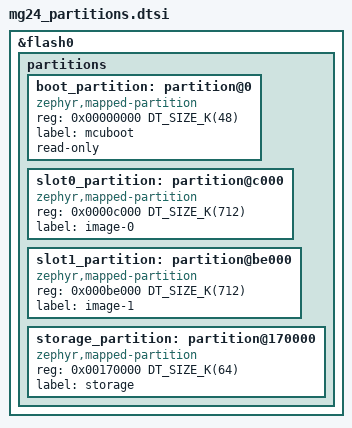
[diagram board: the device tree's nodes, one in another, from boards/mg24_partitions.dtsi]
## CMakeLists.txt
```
# MagNET Hanasu — Zephyr build (XIAO MG24).
#
# The MagNET core and the Forth engine are compiled straight from
# firmware-idf/ — NOT copied — so the two targets cannot drift. What differs
# lives here: compat/ (the FreeRTOS/esp_* subset those sources call, on Zephyr
# primitives), the PSA port of magnet_crypto.c, main.c, and the Z-B bundle stub.
#
#   cd ~/zephyrproject && west build -b xiao_mg24 <this dir> -d build/mn
cmake_minimum_required(VERSION 3.20.0)
find_package(Zephyr REQUIRED HINTS $ENV{ZEPHYR_BASE})
project(magnet_hanasu_zephyr)

set(IDF   ${CMAKE_CURRENT_LIST_DIR}/../firmware-idf)
set(MN    ${IDF}/components/magnet)
set(FORTH ${IDF}/components/forth)
set(CRAW  ${IDF}/components/craw_role_bundle)
set(NACL  ${IDF}/components/magnet_crypto)     # TweetNaCl Ed25519 (bundle signatures)

target_sources(app PRIVATE
    src/main.c
    src/magnet_crypto_psa.c
    src/ota.c
    compat/src/freertos_zephyr.c
    compat/src/nvs_zephyr.c
    compat/src/esp_misc_zephyr.c
    ${MN}/magnet_core.c
    ${MN}/magnet_envelope.c
    ${MN}/magnet_pkg.c
    ${MN}/magnet_link.c
    ${MN}/magnet_forth.c
    ${MN}/magnet_xfer.c
    ${MN}/magnet_bot.c
    ${MN}/magnet_ot.c
    ${FORTH}/forth_core.cpp
)

# compat/include first: it must win over nothing, but it is the ONLY source
# of the esp_* / freertos/* headers on this target.
target_include_directories(app PRIVATE
    compat/include
    ${MN}/include
    ${FORTH}
    ${CRAW}
)

if(CONFIG_MN_OTA_FORCE_UNHEALTHY)   # test builds only; see src/ota.c
  target_compile_definitions(app PRIVATE MN_OTA_FORCE_UNHEALTHY=1)
endif()
if(CONFIG_MN_PKG_RELEASE_KEYS)      # release.conf; see tools/keys/README.md
  target_compile_definitions(app PRIVATE MN_PKG_RELEASE_KEYS=1)
endif()

# BLE-GATT HCP binding: the Zephyr BT-host port when built with ble.conf,
# otherwise the IDF file's own MN_ENABLE_BLE=0 no-op stubs.
if(CONFIG_BT)
  target_sources(app PRIVATE src/magnet_ble_zephyr.c)
  # The BT stack is paid for from the malloc arena (ble.conf: 52 KB), which
  # left a BLE-fed BUNDLE COMMIT 2.5 KB from OOM with a 32 KB Forth heap.
  # Forth heap is allot/create space only (used=0 on the bench) -> 16 KB.
  target_compile_definitions(app PRIVATE MN_ENABLE_BLE=1 MN_FORTH_HEAP_KB=16)
  if(CONFIG_MN_BLE_RESIDENT)       # ble-resident.conf
    target_compile_definitions(app PRIVATE MN_BLE_RESIDENT=1)
  endif()
else()
  target_sources(app PRIVATE ${MN}/magnet_ble.c)
  target_compile_definitions(app PRIVATE MN_ENABLE_BLE=0)
endif()

target_compile_definitions(app PRIVATE
    _DEFAULT_SOURCE          # strlcpy/strcasecmp: newlib shows them by default, picolibc does not
    MN_ENABLE_OPENTHREAD=1
    MN_ENABLE_LED=0          # single PA7 LED; LED verb reports E_UNSUPPORTED
    MN_ENABLE_BOTS=0
)

# The engine takes its re-entrancy lock only under ESP_PLATFORM; this target
# is multi-threaded (link, pump, hooks), so it needs that lock too.
# MAX_WORD_LEN 64→32 saves 16 KB of dictionary BSS (512 entries); the
# longest word any MagNET/bundle code registers is 14 chars.
set_source_files_properties(${FORTH}/forth_core.cpp PROPERTIES
    COMPILE_DEFINITIONS "ESP_PLATFORM=1;MAX_WORD_LEN=32"
    COMPILE_OPTIONS "-Wno-unused-function;-Wno-unused-variable;-Wno-sign-compare;-Wno-write-strings;-Wno-missing-field-initializers")

# PBKDF2 inner loop (software SHA-256): -O3 over the project's -Os. Measured
# with the MN_KAT_TIME_PBKDF2 power-on KAT on the XIAO MG24 @ 78 MHz.
set_source_files_properties(src/magnet_crypto_psa.c PROPERTIES COMPILE_OPTIONS "-O3"
    COMPILE_DEFINITIONS MBEDTLS_DECLARE_PRIVATE_IDENTIFIERS)   # mbedtls_md_hmac KAT

# ---- signed role bundles (H6): craw_role_bundle + TweetNaCl + cJSON ----
# Its own library because the Ed25519 component ships a header ALSO named
# magnet_crypto.h (the core's is the channel/AEAD one). IDF keeps the two
# apart per component; here each target sees only its own.
zephyr_library_named(mn_bundle)
zephyr_library_sources(
    ${CRAW}/craw_role_bundle.c
    ${NACL}/magnet_crypto.c
    ${NACL}/tweetnacl.c
    ${NACL}/nacl_glue.c
    third_party/cJSON/cJSON.c         # MIT, v1.7.x from ESP-IDF 5.3.1 components/json
)
zephyr_library_include_directories(
    compat/include
    ${NACL}/include
    ${NACL}
    ${CRAW}
    ${FORTH}
    third_party/cJSON
)
zephyr_library_compile_definitions(_DEFAULT_SOURCE)
set_source_files_properties(${NACL}/tweetnacl.c PROPERTIES COMPILE_OPTIONS
    "-Wno-shadow;-Wno-sign-compare;-Wno-unused-parameter;-Wno-char-subscripts")
target_include_directories(app PRIVATE third_party/cJSON)
target_link_libraries(app PRIVATE mn_bundle)   # not auto-linked from an app-level zephyr_library
# TF-PSA-Crypto 1.0 moved mbedtls_md_hmac() behind MBEDTLS_DECLARE_PRIVATE_
# IDENTIFIERS; the bundle engine's legacy HMAC-SHA256 check still uses it.
set_source_files_properties(${CRAW}/craw_role_bundle.c PROPERTIES
    COMPILE_DEFINITIONS MBEDTLS_DECLARE_PRIVATE_IDENTIFIERS)
```

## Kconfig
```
# MagNET app options. Kconfig (not -D) because sysbuild forwards conf files to
# the app image but not arbitrary -D cache variables.
source "Kconfig.zephyr"

menu "MagNET Hanasu"

config MN_BLE_RESIDENT
	bool "BLE stays up after provisioning (companion node)"
	depends on BT
	help
	  Keep the BLE-GATT HCP binding up for the life of the node so a phone
	  can use it as its live window into the mesh (magnet_app Option A).
	  Default (n): advertise only while unprovisioned; CHANNEL SET tears
	  the stack down.

config MN_OTA_FORCE_UNHEALTHY
	bool "TEST ONLY: never confirm an OTA image (exercises rollback)"
	help
	  The running image never counts as healthy and the confirm deadline
	  drops to 20 s, so a swapped-in image reboots and MCUboot reverts.

config MN_PKG_RELEASE_KEYS
	bool "OTA key store: release keys (magnet_pkg_keys_release.h)"
	help
	  Trust the release OTA keys generated from PUBLIC halves (see
	  tools/keys/README.md) instead of the committed DEV keys. The build
	  fails if the release header is missing or holds DEV keys. Set by
	  release.conf.

endmenu
```

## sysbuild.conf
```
# Z-F: MCUboot + dual-slot images. Build with --sysbuild.
SB_CONFIG_BOOTLOADER_MCUBOOT=y
SB_CONFIG_BOOT_SIGNATURE_TYPE_ECDSA_P256=y
# SB_CONFIG_BOOT_SIGNATURE_KEY_FILE unset = MCUboot's DEV key. Replace before
# any node leaves the bench — anyone holding the dev key can sign firmware.
# swap-using-MOVE, not the default swap-using-offset: offset mode expects the
# upgrade image one sector INTO slot1, so an image written at the slot start
# is silently ignored (observed). Move mode = images at slot start; slot0
# keeps one spare sector for the shuffle, so max image = 712 KB - 8 KB - trailer.
SB_CONFIG_MCUBOOT_MODE_SWAP_USING_MOVE=y
```

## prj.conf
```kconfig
# MagNET Hanasu on Zephyr — XIAO MG24 (phase Z-B)

# ---- host link: USART0 is BOTH the HCP link and Zephyr's default console.
# Everything that could print to it is off, or it breaks §11.3 framing.
CONFIG_SERIAL=y
# RX by LDMA (async API) — see boards/xiao_mg24.overlay for why
CONFIG_UART_ASYNC_API=y
CONFIG_UART_INTERRUPT_DRIVEN=n
CONFIG_DMA=y
CONFIG_CONSOLE=n
CONFIG_UART_CONSOLE=n
CONFIG_LOG=n
CONFIG_SHELL=n
CONFIG_PRINTK=n
CONFIG_BOOT_BANNER=n

# ---- kernel
# = IDF CONFIG_ESP_MAIN_TASK_STACK_SIZE. Boot re-applies persisted role bundles
# on main (cJSON + TweetNaCl Ed25519 + Forth eval); 4 KB smashed the stack.
CONFIG_MAIN_STACK_SIZE=8192
# xTaskCreate → k_thread_stack_alloc
CONFIG_DYNAMIC_THREAD=y
CONFIG_DYNAMIC_THREAD_ALLOC=y
CONFIG_DYNAMIC_THREAD_PREFER_ALLOC=y
CONFIG_DYNAMIC_THREAD_POOL_SIZE=0
# k_malloc: task stacks (link 8K, pump 8K, stress 4K transient) + queues/timers
CONFIG_HEAP_MEM_POOL_SIZE=28672
# malloc: 32 KB Forth heap + core (low-water 34 KB free at 80 KB; 4 KB went to
# the pump stack / LDMA RX buffers)
CONFIG_COMMON_LIBC_MALLOC_ARENA_SIZE=77824
# SYSINFO / `mem` heap figures
CONFIG_SYS_HEAP_RUNTIME_STATS=y
CONFIG_REBOOT=y
# reset cause, EUI-64
CONFIG_HWINFO=y
CONFIG_GPIO=y

# ---- C++ for the Forth engine (forth_core.cpp uses <cstdio> etc.)
CONFIG_CPP=y
CONFIG_REQUIRES_FULL_LIBCPP=y

# ---- storage (NVS compat + OpenThread dataset share settings)
CONFIG_FLASH=y
CONFIG_FLASH_MAP=y
CONFIG_NVS=y
CONFIG_SETTINGS=y
CONFIG_SETTINGS_RUNTIME=n

# ---- networking / OpenThread (full router, CoAP, configured by magnet_ot.c)
CONFIG_NETWORKING=y
CONFIG_NET_L2_OPENTHREAD=y
CONFIG_OPENTHREAD_FTD=y
CONFIG_OPENTHREAD_COAP=y
CONFIG_OPENTHREAD_MANUAL_START=y
# OT allows ONE state-changed handler by default and Zephyr's L2 takes it;
# without room for magnet_ot.c's, every !ROLE event silently disappears.
CONFIG_OPENTHREAD_MAX_STATECHANGE_HANDLERS=3
# Zephyr's IP stack only ferries single 802.15.4 frames (≤127 B) between the
# radio driver and OpenThread — MagNET's CoAP lives in OT's own message pool.
# Defaults (16 KB of net_buf data) are sized for sockets we never open.
CONFIG_NET_PKT_RX_COUNT=6
CONFIG_NET_PKT_TX_COUNT=6
CONFIG_NET_BUF_RX_COUNT=12
CONFIG_NET_BUF_TX_COUNT=12
CONFIG_NET_MAX_CONTEXTS=2

# ---- crypto (§11.1 on PSA)
# OpenThread's DEFAULT security profile makes every PSA/mbedTLS symbol
# promptless (unsettable), and it has no HKDF. CUSTOM unlocks them — at the
# price of spelling out what the default profile selected. The list below is
# exactly the Z-A spike's resolved config (known good on this board) + HKDF.
CONFIG_OPENTHREAD_SECURITY_CUSTOM_CONFIG=y
CONFIG_SECURE_STORAGE=y
CONFIG_PSA_WANT_KEY_TYPE_AES=y
CONFIG_PSA_WANT_KEY_TYPE_HMAC=y
CONFIG_PSA_WANT_ALG_ECB_NO_PADDING=y
CONFIG_PSA_WANT_ALG_HMAC=y
CONFIG_PSA_WANT_ALG_CCM=y
CONFIG_PSA_WANT_ALG_CMAC=y
CONFIG_PSA_WANT_ALG_SHA_256=y
CONFIG_PSA_WANT_ECC_SECP_R1_256=y
CONFIG_PSA_WANT_KEY_TYPE_ECC_KEY_PAIR_IMPORT=y
CONFIG_PSA_WANT_KEY_TYPE_ECC_KEY_PAIR_EXPORT=y
CONFIG_PSA_WANT_KEY_TYPE_ECC_KEY_PAIR_GENERATE=y
CONFIG_PSA_WANT_KEY_TYPE_ECC_KEY_PAIR_DERIVE=y
CONFIG_PSA_WANT_KEY_TYPE_ECC_PUBLIC_KEY=y
CONFIG_PSA_WANT_ALG_ECDSA=y
CONFIG_PSA_WANT_ALG_DETERMINISTIC_ECDSA=y
CONFIG_PSA_WANT_ALG_ECDH=y
CONFIG_MBEDTLS=y
CONFIG_MBEDTLS_ENABLE_HEAP=y
# The SE has no DETERMINISTIC ECDSA, so mn_sign falls back to software bignum
# math on this heap. The 1 KB default fails with PSA_ERROR_INSUFFICIENT_MEMORY
# (caught by the RFC 6979 power-on KAT).
CONFIG_MBEDTLS_HEAP_SIZE=6144
CONFIG_MBEDTLS_MD_C=y
CONFIG_MBEDTLS_ASN1_PARSE_C=y
CONFIG_MBEDTLS_X509_CRT_PARSE_C=y
CONFIG_MBEDTLS_KEY_EXCHANGE_ECDHE_ECDSA_ENABLED=y
CONFIG_MBEDTLS_PK_WRITE_C=y
CONFIG_MBEDTLS_ECP_NIST_OPTIM=y
# MagNET additions
CONFIG_PSA_WANT_ALG_HKDF=y
# one-shot PBKDF2: native on the Secure Engine for Secure Vault High parts
CONFIG_PSA_WANT_ALG_PBKDF2_HMAC=y
CONFIG_MBEDTLS_BASE64_C=y

# ---- OTA (Z-F): mark a freshly swapped image good once the node is healthy
CONFIG_FLASH_MAP=y
CONFIG_STREAM_FLASH=y
CONFIG_IMG_MANAGER=y
CONFIG_MCUBOOT_IMG_MANAGER=y
```

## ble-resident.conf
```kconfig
# Companion node: BLE resident (use with ble.conf)
CONFIG_MN_BLE_RESIDENT=y
```

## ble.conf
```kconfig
# Z-E: BLE-GATT HCP binding (§11.2.1) — Zephyr BT host + Silabs controller.
#   west build ... -- -DEXTRA_CONF_FILE=ble.conf
# Concurrent BLE + 802.15.4 needs RAIL's multiprotocol library (the driver's
# scheduler-priority Kconfigs only matter on multiprotocol builds).
CONFIG_BT=y
CONFIG_BT_PERIPHERAL=y
CONFIG_BT_DEVICE_NAME="MagNET"
CONFIG_BT_DEVICE_NAME_DYNAMIC=y
CONFIG_BT_MAX_CONN=1
CONFIG_BT_SMP=y
# NOT BT_SMP_SC_ONLY: SC-only mode demands authenticated (MITM) keys, which a
# screenless Just Works node can never produce. Legacy stays as fallback, as
# on the C6 (CONFIG_BT_NIMBLE_SM_LEGACY=y).
# A phone that lost its bond (app reinstall, FACTORY RESET) may pair again —
# NimBLE's REPEAT_PAIRING retry (BLE-PAIRING.md §3).
CONFIG_BT_SMP_ALLOW_UNAUTH_OVERWRITE=y
CONFIG_BT_BONDABLE=y
CONFIG_BT_MAX_PAIRED=4
CONFIG_BT_SETTINGS=y
CONFIG_BT_GATT_DYNAMIC_DB=n
# ATT MTU 247 (client SHOULD request it — §11.2.1)
CONFIG_BT_L2CAP_TX_MTU=247
CONFIG_BT_BUF_ACL_RX_SIZE=251
CONFIG_BT_BUF_ACL_TX_SIZE=251
# Long (prepared) writes: ADMIN ADD <130-hex pubkey> exceeds one ATT payload
CONFIG_BT_ATT_PREPARE_COUNT=4
CONFIG_SILABS_SISDK_RAIL_MULTIPROTOCOL=y
# RAM: the BT host + controller glue costs ~19 KB. Pay for it from the malloc
# arena, whose measured low-water mark (boot bundle re-apply + BUNDLE COMMIT)
# was 34 KB free of 80 KB (46 KB peak use) — 56 KB leaves ~10 KB at that peak.
CONFIG_COMMON_LIBC_MALLOC_ARENA_SIZE=57344
# +4 KB kernel heap for the mn_ble_rx worker's 6 KB stack
CONFIG_HEAP_MEM_POOL_SIZE=28672
```

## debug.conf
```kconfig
# Debug overlay: crash reports on the console. Breaks HCP framing — bring-up
# only. Build with  -- -DEXTRA_CONF_FILE=debug.conf
CONFIG_CONSOLE=y
CONFIG_UART_CONSOLE=y
CONFIG_PRINTK=y
CONFIG_LOG=y
CONFIG_LOG_MODE_MINIMAL=y
CONFIG_ASSERT=y
CONFIG_THREAD_NAME=y
CONFIG_EXTRA_EXCEPTION_INFO=y
CONFIG_INIT_STACKS=y
CONFIG_THREAD_STACK_INFO=y
# stack overflows report as such instead of a garbage EXC_RETURN
CONFIG_MPU_STACK_GUARD=y
# console/log RAM has to come from somewhere: 4 KB off the malloc arena
CONFIG_COMMON_LIBC_MALLOC_ARENA_SIZE=73728
```

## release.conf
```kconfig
# Release build: trust the release OTA keys, not the committed DEV keys.
# Use with -DMN_SIGN_OFFLINE=1 and the PUBLIC MCUboot key — tools/keys/README.md.
CONFIG_MN_PKG_RELEASE_KEYS=y
```

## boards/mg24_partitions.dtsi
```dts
/*
 * XIAO MG24 flash map for MCUboot + dual-slot OTA (Z-F). Shared by the app
 * (boards/xiao_mg24.overlay) and MCUboot (sysbuild/mcuboot.overlay) so the two
 * can never disagree. 1536 KB, 8 KB pages:
 *
 *   0x000000  mcuboot   48 KB
 *   0x00C000  slot0    712 KB   running image
 *   0x0BE000  slot1    712 KB   OTA download / swap partner
 *   0x170000  storage   64 KB   settings: identity key, bonds, channel, OT
 *
 * storage stays at 0x170000 (where the pre-MCUboot build put it) so an
 * upgrade keeps the node's identity and bonds.
 */
&flash0 {
	/delete-node/ partitions;

	partitions {
		ranges;
		#address-cells = <1>;
		#size-cells = <1>;

		boot_partition: partition@0 {
			compatible = "zephyr,mapped-partition";
			reg = <0x00000000 DT_SIZE_K(48)>;
			label = "mcuboot";
			read-only;
		};
		slot0_partition: partition@c000 {
			compatible = "zephyr,mapped-partition";
			reg = <0x0000c000 DT_SIZE_K(712)>;
			label = "image-0";
		};
		slot1_partition: partition@be000 {
			compatible = "zephyr,mapped-partition";
			reg = <0x000be000 DT_SIZE_K(712)>;
			label = "image-1";
		};
		storage_partition: partition@170000 {
			compatible = "zephyr,mapped-partition";
			reg = <0x00170000 DT_SIZE_K(64)>;
			label = "storage";
		};
	};
};
```

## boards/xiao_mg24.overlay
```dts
/* App flash map — see mg24_partitions.dtsi (shared with MCUboot). */
#include "mg24_partitions.dtsi"


/* USART0 (the HCP host link) receives by LDMA, not by interrupt: its RX FIFO
 * is 2 bytes, and the CPU stalls for longer than 2 character times at
 * 115200 whenever flash is erased (an 8 KB page, ~15-20 ms: OTA staging,
 * settings) or the BLE controller's radio interrupts run — measured 0.9 % of
 * HCP lines corrupted with BLE up, and a lost XFER DATA line during OTA. */
&dma0 {
	status = "okay";
};

&usart0 {
	dmas = <&dma0 DMA_REQSEL_USART0RXDATAV>, <&dma0 DMA_REQSEL_USART0TXBL>;
	dma-names = "rx", "tx";
};
```

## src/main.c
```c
/*
 * main.c — MagNET Hanasu node on Zephyr (XIAO MG24), phase Z-B.
 *
 * Same bring-up order as firmware-idf/src/main.c (§12.5), which is
 * load-bearing: transport → forth_init (claim heap first) → storage → core +
 * vocab → link → RADIOS LAST.
 *
 * Host link: USART0 at 115200, which the XIAO's SAMD11 bridges to USB CDC.
 * This UART is ALSO Zephyr's default console, so prj.conf turns the console,
 * shell and logging off — any stray line here breaks HCP framing (§11.3).
 */
#include <zephyr/kernel.h>
#include <zephyr/device.h>
#include <zephyr/drivers/uart.h>
#include <zephyr/sys/ring_buffer.h>
#include <stdio.h>
#include <string.h>

#include "esp_heap_caps.h"
#include "nvs_flash.h"
#include "forth_core.h"
#include "craw_role_bundle.h"
#include "magnet_ota.h"
#include "magnet.h"

/* Half the C6's 64 KB. The Forth heap only backs allot/create data —
 * colon definitions (incl. installed role bundles) live in the engine's
 * static dictionary/code arrays — and SYSINFO showed forth-heap used=0 with
 * two bundles installed, while a BUNDLE COMMIT (6 KB accumulator + cJSON
 * tree + Ed25519) drove the shared malloc arena down to 1.4 KB free. */
#ifndef MN_FORTH_HEAP_KB
#define MN_FORTH_HEAP_KB 32        /* BLE build: 16 (CMakeLists.txt) */
#endif
#define FORTH_HEAP_SIZE (MN_FORTH_HEAP_KB * 1024)

static const struct device *const s_uart = DEVICE_DT_GET(DT_CHOSEN(zephyr_console));

/* ---- RX: LDMA → ring buffer → link_getc ----
 * Received by DMA, not per-byte interrupts: the USART FIFO is 2 bytes and the
 * CPU stalls longer than that at 115200 during flash erases and BLE radio
 * work (see boards/xiao_mg24.overlay). Two 384-byte buffers ping-pong — each
 * holds ~33 ms of line, so a stall up to ~66 ms loses nothing — and a 1 ms
 * idle timeout hands partial buffers over promptly. */
RING_BUF_DECLARE(s_rx_ring, 1024);
static K_SEM_DEFINE(s_rx_sem, 0, 1);
static uint8_t s_dma_buf[2][384];
static uint8_t s_dma_next;
/* The UART has no flow control: if the dispatcher falls > 1 KB behind the
 * wire, bytes are lost. Counted here, reported by link_getc as a !WARN so a
 * host knows its data was dropped (hosts should pace on replies; see
 * tools/ota_push.py). */
static atomic_t s_rx_dropped;

static void uart_cb(const struct device *dev, struct uart_event *evt, void *ud) {
    ARG_UNUSED(ud);
    switch (evt->type) {
    case UART_RX_RDY:
    {
        uint32_t put = ring_buf_put(&s_rx_ring, evt->data.rx.buf + evt->data.rx.offset,
                                    evt->data.rx.len);
        if (put < evt->data.rx.len) atomic_add(&s_rx_dropped, evt->data.rx.len - put);
        k_sem_give(&s_rx_sem);
    }
        break;
    case UART_RX_BUF_REQUEST:
        uart_rx_buf_rsp(dev, s_dma_buf[s_dma_next], sizeof(s_dma_buf[0]));
        s_dma_next ^= 1;
        break;
    case UART_RX_DISABLED:                  /* after an error/stop: start over */
        s_dma_next = 1;
        uart_rx_enable(dev, s_dma_buf[0], sizeof(s_dma_buf[0]), 1000);
        break;
    default:
        break;
    }
}

/* One char, or -1 after ~10 ms — the contract the IDF getc has.
 *
 * NUL bytes are dropped: the SAMD11 bridge injects a 0x00 into the UART when
 * the host opens the port, and a line that starts with NUL parses as empty
 * (the dispatcher answers "-ERR E_SYNTAX empty" and loses the whole command).
 * HCP is text, so a NUL is never meaningful. */
static int link_getc(void) {
    uint8_t c;
    static atomic_val_t reported;
    atomic_val_t dropped = atomic_get(&s_rx_dropped);
    if (dropped != reported) {                   /* dispatcher context: may emit */
        mn_emit_event("!WARN link-rx-overrun dropped=%ld (host: wait for each reply)",
                      (long)(dropped - reported));
        reported = dropped;
    }
    for (;;) {
        if (ring_buf_get(&s_rx_ring, &c, 1) != 1) {
            k_sem_take(&s_rx_sem, K_MSEC(10));
            if (ring_buf_get(&s_rx_ring, &c, 1) != 1) return -1;
        }
        if (c != 0) return c;
    }
}

/* Polled TX. Unlike the C6's on-die USB, the SAMD11 bridge always drains the
 * UART whether or not a host has the port open, so this cannot stall the way
 * link_putc on IDF could (which is why that one drops on a full buffer). */
static void link_putc(int c) { uart_poll_out(s_uart, (unsigned char)c); }

static void raw_print(const char *s) { while (*s) link_putc(*s++); }

static void report_heap(const char *label) {
    char buf[128];
    snprintf(buf, sizeof(buf), "# heap[%s] free=%u min=%u\r\n", label,
             (unsigned)heap_caps_get_free_size(MALLOC_CAP_INTERNAL),
             (unsigned)heap_caps_get_minimum_free_size(MALLOC_CAP_INTERNAL));
    raw_print(buf);
}

int main(void) {
    /* 1. transport up first so we can talk even if everything else stalls */
    if (!device_is_ready(s_uart)) return 0;
    uart_callback_set(s_uart, uart_cb, NULL);
    s_dma_next = 1;
    uart_rx_enable(s_uart, s_dma_buf[0], sizeof(s_dma_buf[0]), 1000);   /* 1 ms idle */

    raw_print("\r\n# MagNET Hanasu — Zephyr/MG24 (Z-B)\r\n");
    report_heap("boot");

    /* 2. claim the Forth dictionary heap while RAM is unfragmented */
    if (forth_init(FORTH_HEAP_SIZE) != 0) {
        raw_print("-ERR E_INTERNAL forth_init failed\r\n");
        return 0;
    }
    report_heap("after forth_init");

    /* 3. storage, then MagNET core + Forth vocab */
    if (nvs_flash_init() != ESP_OK) raw_print("# WARN settings init failed\r\n");
    {   /* power-on crypto KATs: PSA port == C6 mbedTLS */
        extern void mn_crypto_psa_kat(char *out, size_t cap);
        char kat[200];
        mn_crypto_psa_kat(kat, sizeof kat);
        raw_print(kat); raw_print("\r\n");
    }
    mn_core_init();
    mn_register_forth_vocab();
    craw_role_bundle_init();
    {
        int ncaps = 0;
        const char **caps = mn_bundle_caps(&ncaps);
        if (mn_ota_bundles_suspended()) {     /* CLEARS_BUNDLES image on trial (§7.4) */
            raw_print("# ota: CLEARS_BUNDLES image on trial — saved bundles held back\r\n");
        } else {
            if (craw_role_bundle_apply_saved(caps, ncaps) > 0)
                raw_print("# autorun: persisted role bundle(s) re-applied\r\n");
            int found, failed;               /* OTA health: a failed re-apply blocks confirm */
            craw_role_bundle_boot_stats(&found, &failed);
            mn_boot_bundles_set(found, failed);
        }
    }
    if (mn_script_run() == 0) raw_print("# autorun: boot script executed\r\n");

    /* 4. dual-mode host link (HCP default) + serialized TX writer */
    mn_link_start(link_getc, link_putc);
    mn_set_state(MN_BOOTING);
    mn_emit_event("!READY proto=2.1 fw=" MN_FW_VERSION " id=%02x%02x%02x%02x name=%s state=BOOTING",
                  mn_device_id()[0], mn_device_id()[1], mn_device_id()[2], mn_device_id()[3],
                  mn_name_get());
    mn_emit_event("# type CAPS, or HELP. FORTH drops to the engine.");
    {   /* Z-F: report the image and arm the confirm-when-healthy policy */
        extern void mn_ota_boot(void);
        extern void mn_ota_sink_init(void);
        mn_ota_boot();
        mn_ota_sink_init();          /* mesh OTA: "mnpkg:1" packages -> slot1 */
    }

#if MN_BLE_RESIDENT
    /* companion node: attachable for life (see firmware-idf/src/main.c) */
    if (mn_ble_start() == 0) raw_print("# ble: resident (companion node)\r\n");
#elif MN_ENABLE_BLE
    /* provisioning-only: advertise only while still on the default channel,
     * so a power cycle never re-opens a bonding window on a deployed node */
    if (mn_channel_is_default()) {
        if (mn_ble_start() == 0) raw_print("# ble: provisioning window open\r\n");
    } else {
        raw_print("# ble: skipped (already provisioned)\r\n");
    }
#endif

    /* 5. radios LAST. The XIAO MG24's RF switch (PB5 enable, PB4 antenna
     * select) is set by gpio-hogs in the board DTS — nothing to do here,
     * unlike the XIAO C6. */
    mn_set_state(MN_CONFIGURING);
    mn_openthread_start();

    report_heap("after openthread_start");
    return 0;                          /* link, pump and OT run in their own threads */
}
```

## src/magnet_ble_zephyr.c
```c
/*
 * magnet_ble_zephyr.c — BLE-GATT HCP binding (§11.2.1) on the Zephyr BT host.
 *
 * Same contract as firmware-idf/components/magnet/magnet_ble.c (NimBLE):
 * mn_ble_start/stop/running/link_secure/notify, the same GATT service and
 * UUIDs, and every rule docs/BLE-PAIRING.md paid for:
 *   - HCP-AUTH (…0003) is read-encrypted: reading it is what makes a central
 *     pair (centrals ignore a peripheral's Security Request).
 *   - bonding is enforced per verb (E_NOT_BONDED in magnet_link.c), never at
 *     the ATT layer — HCP-CMD is a plain write.
 *   - never dispatch in the ATT write callback: lines go to a worker.
 *   - notifications retry on buffer exhaustion; one lost chunk = no newline.
 *   - message boundary: a write shorter or longer than (MTU-3) completes a
 *     line; exactly (MTU-3) may continue. Long (prepared) writes are
 *     reassembled by offset and flushed once the execute sequence ends.
 *   - Just Works + numeric-comparison auto-accept (screenless node), and a
 *     peer that lost its bond may pair again (SMP_ALLOW_UNAUTH_OVERWRITE).
 *
 * Unlike the C6 build (provisioning-only by default), the MG24's radio is
 * built for concurrent BLE + 802.15.4 (RAIL multiprotocol), so the resident
 * companion mode is the natural one here; MN_BLE_RESIDENT still selects it.
 *
 * Context discipline: BT host callbacks run on the BT RX thread, which must
 * never block — they use mn_post_note() (pump-emitted), never mn_emit_event.
 */
#include <zephyr/kernel.h>
#include <zephyr/bluetooth/bluetooth.h>
#include <zephyr/bluetooth/conn.h>
#include <zephyr/bluetooth/gatt.h>
#include <zephyr/bluetooth/uuid.h>
#include <zephyr/settings/settings.h>
#include <stdio.h>
#include <string.h>

#include "magnet.h"
#include "freertos/FreeRTOS.h"

/* 6d61676e-2d68-6370-0001-0000000000NN — ASCII "magn" "-h" "cp" */
#define MN_UUID(nn) BT_UUID_128_ENCODE(0x6d61676e, 0x2d68, 0x6370, 0x0001, (nn##ULL))
static const struct bt_uuid_128 SVC_UUID  = BT_UUID_INIT_128(MN_UUID(0x000000000000));
static const struct bt_uuid_128 CMD_UUID  = BT_UUID_INIT_128(MN_UUID(0x000000000001));
static const struct bt_uuid_128 EVT_UUID  = BT_UUID_INIT_128(MN_UUID(0x000000000002));
static const struct bt_uuid_128 AUTH_UUID = BT_UUID_INIT_128(MN_UUID(0x000000000003));

static struct bt_conn *s_conn;
static bool s_running;
static bool s_encrypted;

/* ---- inbound: assemble lines, hand them to a worker ---- */
#define MN_BLE_LINE_MAX 256
static char   s_rx[512];
static size_t s_rx_len;
static QueueHandle_t s_rx_q;

static void post_line(void) {
    if (!s_rx_len) return;
    s_rx[s_rx_len] = '\0';
    if (s_rx_q) {
        char item[MN_BLE_LINE_MAX];
        strncpy(item, s_rx, sizeof(item) - 1);
        item[sizeof(item) - 1] = '\0';
        xQueueSend(s_rx_q, item, 0);          /* never block the BT RX thread */
    }
    s_rx_len = 0;
}

static void feed(const uint8_t *data, size_t len, bool write_complete) {
    for (size_t i = 0; i < len; i++) {
        char c = (char)data[i];
        if (c == '\n' || c == '\r') {
            post_line();
            write_complete = false;           /* newline already flushed it */
        } else if (s_rx_len < sizeof(s_rx) - 1) {
            s_rx[s_rx_len++] = c;
        }
    }
    if (write_complete) post_line();
}

static void ble_worker(void *arg) {
    ARG_UNUSED(arg);
    char item[MN_BLE_LINE_MAX];
    for (;;) {
        if (xQueueReceive(s_rx_q, item, portMAX_DELAY) == pdTRUE)
            mn_link_feed_line(item);          /* same dispatcher as the UART */
    }
}

/* A prepared (long) write arrives as a burst of EXECUTE callbacks with no
 * "last chunk" marker; flush the reassembled line shortly after the burst. */
static void long_write_flush(struct k_work *w) {
    ARG_UNUSED(w);
    post_line();
}
static K_WORK_DELAYABLE_DEFINE(s_long_flush, long_write_flush);

static ssize_t cmd_write(struct bt_conn *conn, const struct bt_gatt_attr *attr,
                         const void *buf, uint16_t len, uint16_t offset, uint8_t flags) {
    ARG_UNUSED(attr);
    if (flags & BT_GATT_WRITE_FLAG_PREPARE) return 0;      /* accept; data at execute */
    if (flags & BT_GATT_WRITE_FLAG_EXECUTE) {
        if (offset == 0) s_rx_len = 0;
        feed(buf, len, false);
        k_work_reschedule(&s_long_flush, K_MSEC(20));
        return len;
    }
    uint16_t payload = bt_gatt_get_mtu(conn) - 3;
    feed(buf, len, len != payload);
    return len;
}

static ssize_t auth_read(struct bt_conn *conn, const struct bt_gatt_attr *attr,
                         void *buf, uint16_t len, uint16_t offset) {
    static const char ok[] = "bonded";       /* reaching here = link encrypted */
    return bt_gatt_attr_read(conn, attr, buf, len, offset, ok, sizeof(ok) - 1);
}

static ssize_t evt_read(struct bt_conn *conn, const struct bt_gatt_attr *attr,
                        void *buf, uint16_t len, uint16_t offset) {
    return bt_gatt_attr_read(conn, attr, buf, len, offset, "", 0);
}

/* Subscription is NOT tracked here: for a bonded peer Zephyr restores the
 * stored CCC on reconnect and CoreBluetooth does not rewrite it, so a flag
 * cleared in connected() silently muted every reply after a reboot. The
 * stack is asked at send time instead (bt_gatt_is_subscribed). */
static void evt_ccc_changed(const struct bt_gatt_attr *attr, uint16_t value) {
    ARG_UNUSED(attr); ARG_UNUSED(value);
}

BT_GATT_SERVICE_DEFINE(mn_hcp_svc,
    BT_GATT_PRIMARY_SERVICE(&SVC_UUID),
    /* HCP-CMD: host → node. Plain write — bonding is per-verb (§11.3.4). */
    BT_GATT_CHARACTERISTIC(&CMD_UUID.uuid,
        BT_GATT_CHRC_WRITE | BT_GATT_CHRC_WRITE_WITHOUT_RESP,
        BT_GATT_PERM_WRITE | BT_GATT_PERM_PREPARE_WRITE, NULL, cmd_write, NULL),
    /* HCP-EVT: node → host (attrs[4] is its value, [5] its CCC) */
    BT_GATT_CHARACTERISTIC(&EVT_UUID.uuid, BT_GATT_CHRC_NOTIFY | BT_GATT_CHRC_READ,
        BT_GATT_PERM_READ, evt_read, NULL, NULL),
    BT_GATT_CCC(evt_ccc_changed, BT_GATT_PERM_READ | BT_GATT_PERM_WRITE),
    /* HCP-AUTH: read it to force pairing */
    BT_GATT_CHARACTERISTIC(&AUTH_UUID.uuid, BT_GATT_CHRC_READ,
        BT_GATT_PERM_READ_ENCRYPT, auth_read, NULL, NULL),
);
#define EVT_ATTR (&mn_hcp_svc.attrs[4])

/* ---- outbound: chunk to (MTU-3), client reassembles at '\n' ---- */
void mn_ble_notify(const char *line) {
    struct bt_conn *conn = s_conn;
    if (!s_running || !conn ||
        !bt_gatt_is_subscribed(conn, EVT_ATTR, BT_GATT_CCC_NOTIFY)) return;
    size_t chunk = bt_gatt_get_mtu(conn) - 3;
    size_t len = strlen(line);
    char buf[256];
    if (chunk > sizeof(buf) - 1) chunk = sizeof(buf) - 1;

    for (size_t off = 0; off <= len; off += chunk) {
        size_t n = len - off;
        bool last = n <= chunk;
        if (!last) n = chunk;
        memcpy(buf, line + off, n);
        if (last) buf[n++] = '\n';            /* frame terminator */
        int rc = -ENOMEM;
        for (int attempt = 0; attempt < 12 && rc != 0; attempt++) {
            rc = bt_gatt_notify(conn, EVT_ATTR, buf, n);
            if (rc == -ENOMEM || rc == -ENOBUFS) k_msleep(10);
            else if (rc != 0) return;         /* link gone / not subscribed */
        }
        if (rc != 0 || last) return;
    }
}

/* ---- connection + security callbacks (BT RX thread: post, don't emit) ---- */
static void connected(struct bt_conn *conn, uint8_t err) {
    if (err) return;
    s_conn = bt_conn_ref(conn);
    s_encrypted = false;
    mn_post_note("!STATE PROVISIONING ble-connected");
    /* Ask for security; per BLE-PAIRING.md centrals mostly ignore this and
     * pair on the HCP-AUTH read instead, but it costs nothing. */
    (void)bt_conn_set_security(conn, BT_SECURITY_L2);
}

static void disconnected(struct bt_conn *conn, uint8_t reason) {
    if (conn != s_conn) return;
    bt_conn_unref(s_conn);
    s_conn = NULL;
    s_encrypted = false;
    mn_post_note("# ble: disconnected (reason 0x%02x)", reason);
}

static void start_adv(void);

/* The connection object is free again: only now can connectable advertising
 * restart (doing it in disconnected() fails for lack of a conn slot). */
static void recycled(void) {
    if (s_running) start_adv();
}

static void security_changed(struct bt_conn *conn, bt_security_t level,
                             enum bt_security_err err) {
    ARG_UNUSED(conn);
    s_encrypted = (err == BT_SECURITY_ERR_SUCCESS) && level >= BT_SECURITY_L2;
    mn_post_note("# ble: link %s (level=%d err=%d)",
                 s_encrypted ? "encrypted" : "NOT encrypted", level, err);
}

BT_CONN_CB_DEFINE(mn_conn_cb) = {
    .connected = connected,
    .disconnected = disconnected,
    .recycled = recycled,
    .security_changed = security_changed,
};

/* Numeric comparison can still be requested under Secure Connections even
 * though we have no I/O; a screenless node accepts (BLE-PAIRING.md §2). */
static void passkey_confirm(struct bt_conn *conn, unsigned int passkey) {
    ARG_UNUSED(passkey);
    bt_conn_auth_passkey_confirm(conn);
}
static void pairing_cancel(struct bt_conn *conn) { ARG_UNUSED(conn); }
static struct bt_conn_auth_cb s_auth = {
    .passkey_confirm = passkey_confirm,
    .cancel = pairing_cancel,
};

static void mtu_updated(struct bt_conn *conn, uint16_t tx, uint16_t rx) {
    ARG_UNUSED(conn);
    mn_post_note("# ble: mtu negotiated tx=%u rx=%u", tx, rx);
}
static struct bt_gatt_cb s_gatt_cb = { .att_mtu_updated = mtu_updated };

/* ---- advertising: 128-bit service UUID in the advert, name in the scan
 * response (a host must be able to filter by service — BLE-PAIRING.md) ---- */
static const struct bt_data s_ad[] = {        /* file scope: BT_DATA_BYTES */
    BT_DATA_BYTES(BT_DATA_FLAGS, BT_LE_AD_GENERAL | BT_LE_AD_NO_BREDR),
    BT_DATA_BYTES(BT_DATA_UUID128_ALL, MN_UUID(0x000000000000)),
};

static void start_adv(void) {
    const char *name = bt_get_name();
    struct bt_data sd[] = { BT_DATA(BT_DATA_NAME_COMPLETE, name, strlen(name)) };
    int rc = bt_le_adv_start(BT_LE_ADV_CONN_FAST_1, s_ad, ARRAY_SIZE(s_ad), sd, ARRAY_SIZE(sd));
    if (rc && rc != -EALREADY) mn_post_note("!WARN ble-adv-start rc=%d", rc);
}

int mn_ble_start(void) {
    if (s_running) return 0;
    static bool once;
    if (!once) {
        bt_conn_auth_cb_register(&s_auth);
        bt_gatt_cb_register(&s_gatt_cb);
        s_rx_q = xQueueCreate(6, MN_BLE_LINE_MAX);
        /* 6 KB like IDF's mn_ble_rx: BLE-fed verbs run here (incl. BUNDLE) */
        xTaskCreate(ble_worker, "mn_ble_rx", 6144, NULL, 5, NULL);
        once = true;
    }
    int rc = bt_enable(NULL);
    if (rc && rc != -EALREADY) return -1;
    /* bonds + identity live in settings under "bt" */
    settings_load_subtree("bt");

    char name[24];
    const uint8_t *id = mn_device_id();
    snprintf(name, sizeof(name), "MagNET-%02x%02x", id[2], id[3]);
    bt_set_name(name);

    s_running = true;
    start_adv();
#if MN_BLE_RESIDENT
    mn_post_note("# ble: advertising (resident — survives provisioning)");
#else
    mn_post_note("# ble: advertising for provisioning (torn down once a channel is set)");
#endif
    return 0;
}

int mn_ble_stop(void) {
    if (!s_running) return 0;
    s_running = false;
    bt_le_adv_stop();
    if (s_conn) bt_conn_disconnect(s_conn, BT_HCI_ERR_REMOTE_USER_TERM_CONN);
    int rc = bt_disable();
    mn_post_note("# ble: torn down (channel provisioned); radio is Thread-only now");
    return rc;
}

bool mn_ble_running(void) { return s_running; }
bool mn_ble_link_secure(void) { return s_encrypted; }
```

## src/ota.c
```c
/*
 * ota.c — MCUboot image health policy (Z-F).
 *
 * After MCUboot swaps in a new image it runs in "test" state: unless the app
 * confirms it, the NEXT reset swaps the old image back. We confirm only once
 * the node is demonstrably healthy — Thread attached, state READY (a lone
 * node still gets there by becoming leader) — and if that has not happened
 * within MN_OTA_CONFIRM_DEADLINE, we reboot so MCUboot rolls back rather
 * than leave a broken image running on a node nobody can reach.
 */
#include <zephyr/kernel.h>
#include <zephyr/dfu/mcuboot.h>
#include <zephyr/storage/flash_map.h>
#include <zephyr/sys/reboot.h>

#include "magnet.h"
#include "magnet_ota.h"

/* MN_OTA_FORCE_UNHEALTHY (test builds only): never counts as healthy and
 * gives up after 20 s — exercises the automatic rollback path end to end. */
#if MN_OTA_FORCE_UNHEALTHY
#define MN_OTA_CONFIRM_DEADLINE_S 20
#define MN_NODE_HEALTHY() false
#else
#define MN_OTA_CONFIRM_DEADLINE_S (10 * 60)
#define MN_NODE_HEALTHY() mn_ota_node_healthy()   /* READY + bundles re-applied (§7.4) */
#endif
#define MN_OTA_POLL_MS            2000

static int64_t s_deadline_ms;

static void confirm_poll(struct k_work *w);
static K_WORK_DELAYABLE_DEFINE(s_confirm_work, confirm_poll);

static void confirm_poll(struct k_work *w) {
    ARG_UNUSED(w);
    if (MN_NODE_HEALTHY()) {
        int rc = boot_write_img_confirmed();
        mn_emit_event(rc == 0 ? "!OTA confirmed (node healthy)"
                              : "!WARN ota-confirm-failed rc=%d", rc);
        mn_ota_settled();                    /* §13.4 report, if an apply is on record */
        return;
    }
    if (k_uptime_get() >= s_deadline_ms) {
        mn_emit_event("!WARN ota-unhealthy: not READY in %ds, rebooting to roll back",
                      MN_OTA_CONFIRM_DEADLINE_S);
        k_msleep(200);                       /* let the line drain */
        sys_reboot(SYS_REBOOT_COLD);
    }
    k_work_reschedule(&s_confirm_work, K_MSEC(MN_OTA_POLL_MS));
}

/* "# ota: running ..." — at boot and from ota-status. True if confirmed. */
static bool report_running(void) {
    struct mcuboot_img_header hdr;
    int rc = boot_read_bank_header(PARTITION_ID(slot0_partition), &hdr, sizeof(hdr));
    bool confirmed = boot_is_img_confirmed();
    if (rc == 0) {
        mn_emit_event("# ota: running v%u.%u.%u+%u (slot0) %s",
                      hdr.h.v1.sem_ver.major, hdr.h.v1.sem_ver.minor,
                      hdr.h.v1.sem_ver.revision, hdr.h.v1.sem_ver.build_num,
                      confirmed ? "confirmed" : "TEST — confirms when READY");
    } else {
        mn_emit_event("# ota: no MCUboot header (rc=%d) — not booted via MCUboot?", rc);
    }
    return confirmed;
}

/* Called once from main after the link is up (events can be emitted). */
void mn_ota_boot(void) {
    bool confirmed = report_running();
    if (confirmed) mn_ota_settled();         /* PERMANENT apply, or the old image after a rollback */
    if (!confirmed) {
        s_deadline_ms = k_uptime_get() + MN_OTA_CONFIRM_DEADLINE_S * 1000LL;
        k_work_reschedule(&s_confirm_work, K_MSEC(MN_OTA_POLL_MS));
    }
}

/* ======================= mesh OTA receive sink =============================
 *
 * Receives an OTA package (docs/OTA-PACKAGE.md, wire format 1) carried by a
 * Type 6 transfer with meta "mnpkg:1" and stages it in MCUboot slot1.
 * The node has no host to stream to, so the xfer sink hands us each verified,
 * de-duplicated chunk:
 *   chunk 0     -> the 256-byte header is checked at once (§4 checks 1-6) and
 *                  a bad package is refused before its payload crosses the air
 *   every chunk -> payload bytes land in slot1 at package offset - 256
 *   completion  -> check 7 (SHA-256 read back from slot1), 8 (MCUboot header
 *                  consistent), 9 (min_running); any failure answers the sender
 *                  "refused:<check>" instead of COMPLETE (§7.1)
 * Applying stays a separate privileged step (Forth `ota-apply`; the
 * admin-signed mesh apply is next). Authenticity: the package signature here,
 * and MCUboot re-checks its own at boot (§5.2).
 */
#include <zephyr/drivers/flash.h>
#include <string.h>
#include "magnet_xfer.h"
#include "magnet_pkg.h"
#include "magnet_pkg_keys.h"
#include "forth_core.h"

#define OTA_PAGE         8192u
#define OTA_MAX_PAGES    96u                      /* 712 KB / 8 KB = 89 */
#define OTA_TAIL_RESERVE (2u * OTA_PAGE)          /* move-mode sector + trailer */
#define OTA_BOARD_XIAO_MG24 0x0201                /* registry §3.1 */

static struct {
    const struct flash_area *fa;
    bool          active, have_hdr, staged;
    uint32_t      total;                          /* package bytes announced */
    uint8_t       raw[MN_PKG_HDR_LEN];
    mn_pkg_hdr_t  hdr;
    mn_pkg_self_t self;
    uint8_t       erased[OTA_MAX_PAGES / 8];
} s_ota;

static int page_ready(uint32_t page) {
    if (s_ota.erased[page >> 3] & (1u << (page & 7))) return 0;
    int rc = flash_area_erase(s_ota.fa, page * OTA_PAGE, OTA_PAGE);
    if (rc == 0) s_ota.erased[page >> 3] |= (1u << (page & 7));
    return rc;
}

/* what this node is, for §4 checks 4, 6 and 9 */
static void self_fill(void) {
    struct mcuboot_img_header h;
    memset(&s_ota.self, 0, sizeof(s_ota.self));
    s_ota.self.chip = MN_PKG_CHIP_EFR32MG24;
    s_ota.self.board = OTA_BOARD_XIAO_MG24;
    s_ota.self.image_format = MN_PKG_FMT_MCUBOOT;
    s_ota.self.slot_size = s_ota.fa->fa_size - OTA_TAIL_RESERVE;
    if (boot_read_bank_header(PARTITION_ID(slot0_partition), &h, sizeof(h)) == 0) {
        s_ota.self.running = (mn_pkg_ver_t){ h.h.v1.sem_ver.major, h.h.v1.sem_ver.minor,
                                             h.h.v1.sem_ver.revision, h.h.v1.sem_ver.build_num };
    }
}

static bool ota_claim(const uint8_t sender_id[4], const char *meta,
                      uint32_t total_len, uint16_t chunk_len) {
    if (strcmp(meta, "mnpkg:1") != 0) return false;         /* not ours: host path */
    s_ota.active = s_ota.have_hdr = s_ota.staged = false;
    if (chunk_len < MN_PKG_HDR_LEN) {                       /* header must fit chunk 0 */
        mn_post_note("!WARN ota: chunk %u B cannot carry the 256 B header", chunk_len);
        return false;
    }
    if (!s_ota.fa && flash_area_open(PARTITION_ID(slot1_partition), &s_ota.fa) != 0) {
        mn_post_note("!WARN ota: cannot open slot1");
        return false;
    }
    self_fill();
    memset(s_ota.erased, 0, sizeof(s_ota.erased));
    /* A stale trailer (an earlier staged/tested image) must not survive:
     * MCUboot reads it to decide whether a swap is pending. */
    if (page_ready(s_ota.fa->fa_size / OTA_PAGE - 1) != 0) return false;
    s_ota.total = total_len;
    s_ota.active = true;
    mn_post_note("!OTA receiving package, %u B from %02x%02x%02x%02x",
                 (unsigned)total_len, sender_id[0], sender_id[1], sender_id[2], sender_id[3]);
    return true;
}

static int ota_chunk(uint16_t idx, uint32_t off, const uint8_t *data, size_t len) {
    if (!s_ota.active) return MN_PKG_E_SIZE;
    if (off < MN_PKG_HDR_LEN) {                             /* chunk 0: the header */
        memcpy(s_ota.raw, data, MN_PKG_HDR_LEN);
        int rc = mn_pkg_check_header(s_ota.raw, s_ota.total, &s_ota.self, &s_ota.hdr);
        if (rc) {
            mn_post_note("!OTA refused %s (check %d) at the header", mn_pkg_rc_name(rc), rc);
            s_ota.active = false;
            return rc;
        }
        s_ota.have_hdr = true;
        data += MN_PKG_HDR_LEN;                             /* rest of chunk 0 = payload */
        len  -= MN_PKG_HDR_LEN;
        off   = MN_PKG_HDR_LEN;
    }
    if (!len) return 0;
    uint32_t so = off - MN_PKG_HDR_LEN;                     /* slot offset, 16-aligned */
    if (so + len > s_ota.fa->fa_size - OTA_TAIL_RESERVE) return MN_PKG_E_SIZE;
    for (uint32_t p = so / OTA_PAGE; p <= (so + len - 1) / OTA_PAGE; p++)
        if (page_ready(p) != 0) return MN_PKG_E_IMAGE;
    uint8_t buf[MN_XFER_CHUNK + 4];                         /* flash writes are 4-aligned */
    size_t n = (len + 3) & ~(size_t)3;
    memcpy(buf, data, len);
    memset(buf + len, 0xff, n - len);
    (void)idx;
    return flash_area_write(s_ota.fa, so, buf, n) == 0 ? 0 : MN_PKG_E_IMAGE;
}

static int slot_read(void *ctx, uint32_t off, void *buf, size_t len) {
    ARG_UNUSED(ctx);
    return flash_area_read(s_ota.fa, off, buf, len);
}

static int ota_done(bool complete) {
    if (!s_ota.active) return 0;
    s_ota.active = false;
    if (!complete) { mn_post_note("!WARN ota: transfer ended early, nothing staged"); return 0; }
    if (!s_ota.have_hdr) return MN_PKG_E_FORMAT;            /* cannot happen: chunk 0 is required */

    int rc = mn_pkg_check_payload(&s_ota.hdr, slot_read, NULL);           /* 7 */
    if (rc == MN_PKG_OK) {                                                 /* 8 */
        struct mcuboot_img_header mh;
        if (boot_read_bank_header(PARTITION_ID(slot1_partition), &mh, sizeof(mh)) != 0 ||
            mh.h.v1.image_size == 0 || mh.h.v1.image_size >= s_ota.hdr.image_len)
            rc = MN_PKG_E_IMAGE;
    }
    if (rc == MN_PKG_OK) rc = mn_pkg_check_min_running(&s_ota.hdr, &s_ota.self);   /* 9 */
    if (rc) {
        mn_post_note("!OTA refused %s (check %d)", mn_pkg_rc_name(rc), rc);
        return rc;
    }
    s_ota.staged = true;
    const uint8_t *id = mn_pkg_sha128(&s_ota.hdr);
    mn_post_note("!OTA staged v%u.%u.%u+%u %02x%02x%02x%02x%02x%02x%02x%02x "
                 "(%u B, key %02x%02x%02x%02x) — FORTH: ota-apply",
                 s_ota.hdr.version.major, s_ota.hdr.version.minor, s_ota.hdr.version.revision,
                 (unsigned)s_ota.hdr.version.build, id[0], id[1], id[2], id[3], id[4], id[5],
                 id[6], id[7], (unsigned)s_ota.hdr.image_len, s_ota.hdr.key_id[0],
                 s_ota.hdr.key_id[1], s_ota.hdr.key_id[2], s_ota.hdr.key_id[3]);
    return 0;
}

static const mn_xfer_sink_t s_ota_sink = {
    .claim = ota_claim, .on_chunk = ota_chunk, .on_done = ota_done,
};

/* Forth: ota-status ( -- )  ota-apply ( -- )  — privileged via FORTH verb */
static void w_ota_status(void) {
    (void)report_running();
    if (!s_ota.staged) {
        mn_emit_event("# ota: slot1 not staged%s", s_ota.active ? " (receiving)" : "");
        return;
    }
    const uint8_t *id = mn_pkg_sha128(&s_ota.hdr);
    mn_emit_event("# ota: slot1 STAGED v%u.%u.%u+%u sha128 %02x%02x%02x%02x%02x%02x%02x%02x… "
                  "variant %s fw %s",
                  s_ota.hdr.version.major, s_ota.hdr.version.minor, s_ota.hdr.version.revision,
                  (unsigned)s_ota.hdr.version.build, id[0], id[1], id[2], id[3], id[4], id[5],
                  id[6], id[7], s_ota.hdr.variant, s_ota.hdr.fw_version);
}

static void w_ota_apply(void) {
    if (!s_ota.staged) { mn_emit_event("-ERR E_BAD_STATE nothing staged"); return; }
    mn_ota_note_arm(&s_ota.hdr);
    int rc = boot_request_upgrade(BOOT_UPGRADE_TEST);
    if (rc) { mn_emit_event("-ERR E_INTERNAL boot_request_upgrade rc=%d", rc); return; }
    mn_emit_event("!OTA applying: rebooting into the staged image (TEST; confirms when healthy)");
    k_msleep(300);
    sys_reboot(SYS_REBOOT_COLD);
}

/* §13.3 hooks for the core's admin-signed apply */
bool mn_ota_platform_supported(void) { return true; }
const mn_pkg_hdr_t *mn_ota_platform_staged(void) {
    return (s_ota.staged && !s_ota.active) ? &s_ota.hdr : NULL;
}
void mn_ota_platform_running(mn_pkg_ver_t *v) {
    struct mcuboot_img_header h;
    memset(v, 0, sizeof(*v));
    if (boot_read_bank_header(PARTITION_ID(slot0_partition), &h, sizeof(h)) == 0)
        *v = (mn_pkg_ver_t){ h.h.v1.sem_ver.major, h.h.v1.sem_ver.minor,
                             h.h.v1.sem_ver.revision, h.h.v1.sem_ver.build_num };
}
bool mn_ota_platform_trial(void) { return !boot_is_img_confirmed(); }
const char *mn_ota_platform_slot(void) { return "slot0"; }
int mn_ota_platform_arm(uint8_t mode) {
    int rc = boot_request_upgrade(mode == MN_OTA_MODE_PERMANENT ? BOOT_UPGRADE_PERMANENT
                                                                : BOOT_UPGRADE_TEST);
    if (rc) mn_emit_event("!WARN ota-arm-failed rc=%d", rc);
    return rc ? -1 : 0;
}

void mn_ota_sink_init(void) {
    mn_xfer_set_sink(&s_ota_sink);
#if MN_PKG_KEYS_ARE_DEV
    mn_emit_event("!WARN ota-dev-keys: trusts the committed DEV release keys — bench only "
                  "(tools/keys/README.md)");
#endif
    forth_register_word("ota-status", w_ota_status);
    forth_register_word("ota-apply", w_ota_apply);
}
```
